# DA14531 register map
Vendor: Dialog; Series: DA14531; File version: 1.2
CPU: CM0 r1p0, little endian, MPU, FPU, 3 interrupt priority bits
Registers are 16-bit, read-write, reset 0x0 unless marked. A register's access mark holds for its fields unless they carry their own. Offsets are from the block's base; [hi:lo] are bit positions; <NAME> marks a mode.

## CRG_TOP — CRG_TOP registers
Base 0x50000000
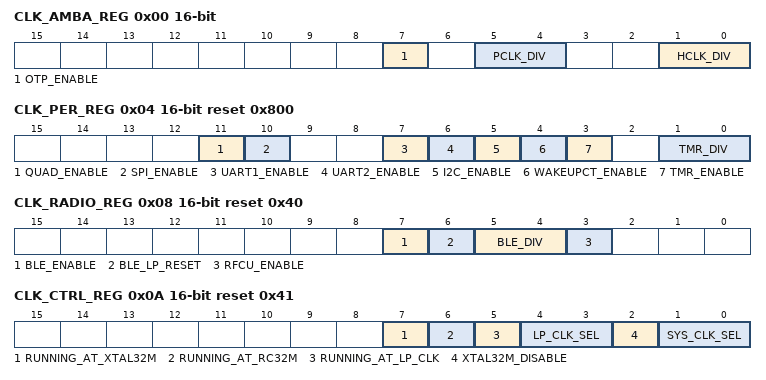
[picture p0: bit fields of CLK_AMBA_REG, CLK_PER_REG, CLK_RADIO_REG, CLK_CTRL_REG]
0x00 CLK_AMBA_REG — HCLK, PCLK, divider and clock gates
  [7] OTP_ENABLE — Clock enable for OTP controller
  [5:4] PCLK_DIV — APB interface clock (PCLK). Divider is cascaded with HCLK_DIV. PCLK is HCLK divided by: 0x0: divide by 1 0x1: divide by 2 0x2: divide by 4 0x3: divide by 8
  [1:0] HCLK_DIV — AHB interface and microprocessor clock (HCLK). HCLK is source clock divided by: 0x0: divide by 1 0x1: divide by 2 0x2: divide by 4 0x3: divide by 8
0x02 CLK_FREQ_TRIM_REG — Xtal frequency trimming register
  [7:0] XTAL32M_TRIM — Xtal frequency fine trimming register. 0x00: highest frequency 0xFF: lowest frequency
0x04 CLK_PER_REG reset 0x800 — Peripheral divider register
  [11] QUAD_ENABLE — Enable the Quadrature clock
  [10] SPI_ENABLE — Enable SPI clock
  [7] UART1_ENABLE — Enable UART1 clock
  [6] UART2_ENABLE — Enable UART2 clock
  [5] I2C_ENABLE — Enable I2C clock
  [4] WAKEUPCT_ENABLE — Enable Wakeup CaptureTimer clock
  [3] TMR_ENABLE — Enable TIMER0 and TIMER2 clock
  [1:0] TMR_DIV — Division factor for TIMER0 0x0: divide by 1 0x1: divide by 2 0x2: divide by 4 0x3: divide by 8
0x08 CLK_RADIO_REG reset 0x40 — Radio PLL control register
  [7] BLE_ENABLE — Enable the BLE core clocks
  [6] BLE_LP_RESET — Reset for the BLE LP timer
  [5:4] BLE_DIV — Division factor for BLE core blocks 0x0: divide by 1 0x1: divide by 2 0x2: divide by 4 0x3: divide by 8 The programmed frequency should not be lower than 8 MHz and not faster than the programmed CPU clock frequency. Refer also to BLE_CNTL2_REG[BLE_CLK_SEL].
  [3] RFCU_ENABLE — Enable the RF control Unit clock
0x0A CLK_CTRL_REG reset 0x41 — Clock control register
  [7] RUNNING_AT_XTAL32M ro — Indicates that the XTAL32M clock is used as clock, and may not be switched off
  [6] RUNNING_AT_RC32M ro — Indicates that the RC32M clock is used as clock
  [5] RUNNING_AT_LP_CLK ro — Indicates that either the LP_CLK is being used as system clock
  [4:3] LP_CLK_SEL — Sets the clock source of the LowerPower clock 0x0: RC32K 0x1: RCX 0x2: XTAL32K through the oscillator with an external Crystal. 0x3: XTAL32K through an external square wave generator (set PID of P0[3] to FUNC_GPIO) Change this setting before using this clock, and while RUNNING_AT_LP_CLK == 0.
  [2] XTAL32M_DISABLE — Setting this bit instantaneously disables the 32 MHz crystal oscillator. Also, after sleep/wakeup cycle, the oscillator will not be enabled. This bit may not be set to '1'when "RUNNING_AT_XTAL32M is '1' to prevent deadlock. After resetting this bit, wait for XTAL32M_SETTLED or XTAL32M_TRIM_READY to become '1' before switching to XTAL32M clock source.
  [1:0] SYS_CLK_SEL — Selects the clock source. 0x0: XTAL32M (check the XTAL32M_SETTLED and XTAL32M_TRIM_READY bits!!) 0x1: RC32M 0x2/0x3: LP_CLK
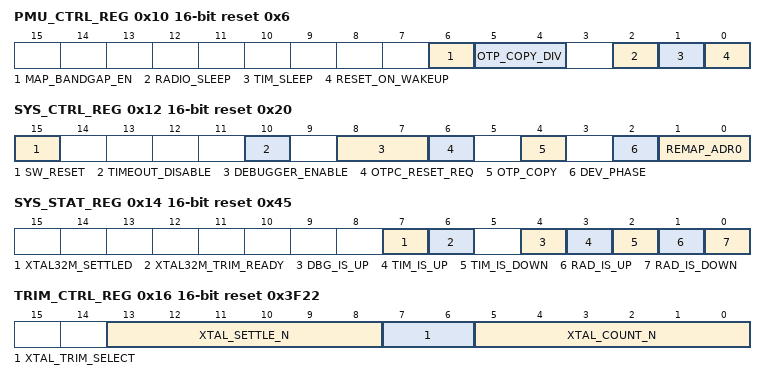
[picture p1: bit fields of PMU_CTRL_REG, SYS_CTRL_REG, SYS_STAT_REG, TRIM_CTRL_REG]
0x10 PMU_CTRL_REG reset 0x6 — Power Management Unit control register
  [6] MAP_BANDGAP_EN — Enable wakeup diagnostics mapping. When set, these functions are mapped (please set direction to output) P0[2]: BANDGAP_ENABLE P0[1]: Power WOKENUP Note: P0[2] assigned also to SWD_CLK, thus the debugger must be detached before entering into sleep mode with MAP_BANDGAP_EN=1. Refer also to SYS_STAT_REG->DBG_IS_UP.
  [5:4] OTP_COPY_DIV — Sets the HCLK division during OTP mirroring
  [2] RADIO_SLEEP — Put the digital part of the radio in powerdown
  [1] TIM_SLEEP — Put PD_TIM in powerdown
  [0] RESET_ON_WAKEUP — Perform a Hardware Reset after waking up. Booter will be started.
0x12 SYS_CTRL_REG reset 0x20 — System Control register
  [15] SW_RESET wo — Writing a '1' to this bit will reset the device, except for: SYS_CTRL_REG CLK_FREQ_TRIM_REG ...
  [10] TIMEOUT_DISABLE — Disables timeout in Power statemachine. By default, the statemachine continues if after 2 ms the blocks are not started up. This can be read back from ANA_STATUS_REG.
  [8:7] DEBUGGER_ENABLE — Enable the debugger. This bit is set by the booter according to the OTP header. If not set, the SWDIO and SW_CLK can be used as gpio ports. 0x0: no debugger enabled. 0x1: SW_CLK = P0[2], SW_DIO=P0[5] 0x2: SW_CLK = P0[2], SW_DIO=P0[1] 0x3: SW_CLK = P0[2], SW_DIO=P0[10]
  [6] OTPC_RESET_REQ — Reset request for the OTP controller.
  [4] OTP_COPY — Enables OTP to SysRAM copy action after waking up PD_SYS
  [2] DEV_PHASE — Sets the development phase mode. If this bit is set, in combination with the OTP_COPY bit, the OTP DMA will emulate the OTP mirroring to System RAM. No actual writing to RAM is done, but the exact same amount of time is spend as if the mirroring would take place. This is to mimic the behavior as if the System Code is already in OTP, and the mirroring takes place after waking up, but the (development) code still resides in an external source. If this bit is set to '0' and OTP_COPY='1', then the OTP DMA will actually do the OTP mirroring at wakeup.
  [1:0] REMAP_ADR0 — Controls which memory is located at address 0x0000 for execution. 0x0: ROM 0x1: OTP 0x2: RAM (SysRAM1) 0x3: RAM (SysRAM3, 28 kBytes offset) This bitfield only takes affect after a Software Reset.
0x14 SYS_STAT_REG reset 0x45 — System status register
  [7] XTAL32M_SETTLED ro — Indicates that XTAL32M has had its settle time, as defined by TRIM_CTRL_REG[XTAL_SETTLE_N]
  [6] XTAL32M_TRIM_READY ro — Indicates that XTAL trimming mechanism is ready, i.e. the trimming equals CLK_FREQ_TRIM_REG.
  [4] DBG_IS_UP ro — Indicates that the SW debugger is attached and in connection with the ARM.
  [3] TIM_IS_UP ro — Indicates that PD_TIM is functional
  [2] TIM_IS_DOWN ro — Indicates that PD_TIM is in power down
  [1] RAD_IS_UP ro — Indicates that PD_RAD is functional
  [0] RAD_IS_DOWN ro — Indicates that PD_RAD is in power down
0x16 TRIM_CTRL_REG reset 0x3F22 — Control trimming of the XTAL32M
  [13:8] XTAL_SETTLE_N — Designates that the XTAL can be safely used as the CPU clock. When XTAL_CLK_CNT reases this value, the signal XTAL32M_SETTLED bit in the SYS_STAT_REG will be set. Counts in steps of 64 xtal clock-cycles.
  [7:6] XTAL_TRIM_SELECT — Select which source controls the XTAL trimming 0b00: xtal counter. Starts XTAL32M_START_REG[XTAL32M_START] after COUNT_N * 32 xtal pulses trim is changed to CLK_FREQ_TRIM_REG[XTAL32M_TRIM]. 0b01: xtal OK filter. Starts with CLK_FREQ_TRIM_REG[XTAL32M_START], when xtal amplitude is ramping is changed to CLK_FREQ_TRIM_REG[XTAL32M_TRIM]. 0b10: statically forced off. Only uses CLK_FREQ_TRIM_REG[XTAL32M_TRIM]. 0b11: xtal OK filter, 2 stage. Starts with CLK_FREQ_TRIM_REG[XTAL32M_START] switches to CLK_FREQ_TRIM_REG[XTAL32M_RAMP] after timeout (32us), and switches to CLK_FREQ_TRIM_REG[XTAL32M_TRIM] when xtal amplitude is ramping up.
  [5:0] XTAL_COUNT_N — Defines the number of XTAL cycles to be counted, before the xtal trimming is applied, in steps of 64 cycles. 0x01: 64 0x02: 128 0x3f: 4032
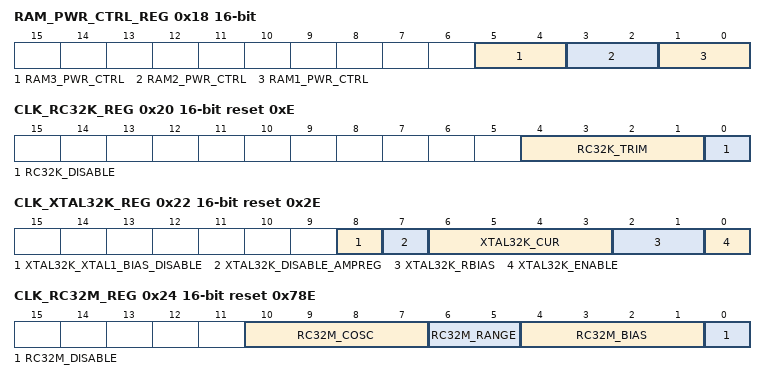
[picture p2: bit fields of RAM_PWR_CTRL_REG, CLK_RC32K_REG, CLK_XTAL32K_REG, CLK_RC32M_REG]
0x18 RAM_PWR_CTRL_REG — Control power state of System RAMS
  [5:4] RAM3_PWR_CTRL — See description of RAM1_PWR_CTRL.
  [3:2] RAM2_PWR_CTRL — See description of RAM1_PWR_CTRL.
  [1:0] RAM1_PWR_CTRL — Power state control of the individual RAMs. May only change when the memory isn't accessed. When in Active or Sleep mode: 0x0: Normal operation 0x1: Normal operation 0x2: Retained (no access possible) 0x3: Off (memory content corrupted) When in Extended Sleep, Deep Sleep or Hibernation mode 0x0: Retained 0x1: Off (memory content corrupted) 0x2: Retained 0x3: Off (memory content corrupted)
0x20 CLK_RC32K_REG reset 0xE — 32 kHz RC oscillator register
  [4:1] RC32K_TRIM — 0000 = lowest frequency 0111 = default 1111 = highest frequency
  [0] RC32K_DISABLE — Instantly disables the 32kHz RC oscillator Sleep cycles cannot happen with this clock disabled.
0x22 CLK_XTAL32K_REG reset 0x2E — 32 kHz XTAL oscillator register
  [8] XTAL32K_XTAL1_BIAS_DISABLE
  [7] XTAL32K_DISABLE_AMPREG — Setting this bit disables the amplitude regulation of the XTAL32kHz oscillator. Set this bit to '1' for an external clock to XTAL32Kp Keep this bit '0' with a crystal between XTAL32Kp and XTAL32Km
  [6:3] XTAL32K_CUR — Bias current for the 32kHz XTAL oscillator. 0000 is minimum, 1111 is maximum, 0011 is default. For each application there is an optimal setting for which the start-up behavior is optimal
  [2:1] XTAL32K_RBIAS — Setting for the bias resistor. 00 is maximum, 11 is minimum. Prefered setting will be provided by Dialog
  [0] XTAL32K_ENABLE — Enables the 32kHz XTAL oscillator. Also set GP_DATA_REG[P03_P04_FILT_DIS] = 1 for lowest current consumption.
0x24 CLK_RC32M_REG reset 0x78E — Fast RC control register
  [10:7] RC32M_COSC — C-adjust of RC-oscillator A higher value of COSC results in a lower frequency
  [6:5] RC32M_RANGE — Coarse adjust A higher value of RANGE results in a higher frequency, values 2 and 3 are equal
  [4:1] RC32M_BIAS — Bias adjustment
  [0] RC32M_DISABLE — Instantly disables the 32MHz RC oscillator Disabling of the oscillator during sleep happens automatically.
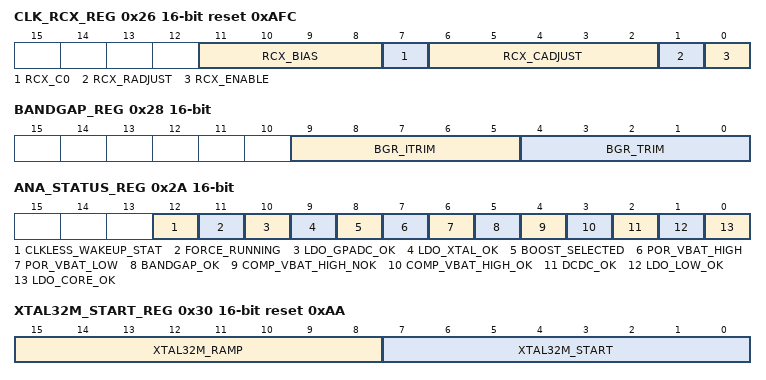
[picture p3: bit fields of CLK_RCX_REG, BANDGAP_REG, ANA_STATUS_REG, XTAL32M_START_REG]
0x26 CLK_RCX_REG reset 0xAFC — RCX-oscillator control register
  [11:8] RCX_BIAS — LDO bias current. 0x0: minimum 0xF: maximum
  [7] RCX_C0 — Add unit capacitance to RC-time delay.
  [6:2] RCX_CADJUST — Adjust capacitance part of RC-time delay. 0x00: minimum capacitance 0x1F: maximum capacitance
  [1] RCX_RADJUST — Adjust resistance part of RC-time delay. Lower resistance increases power consumption. 0x0: maximum resistance 0x1: minimum resistance
  [0] RCX_ENABLE — Enable the RCX oscillator
0x28 BANDGAP_REG — Bandgap trimming
  [9:5] BGR_ITRIM — Trim setting for bandgap bias current 10000 -> -25% .... 11111 -> ~0% 00000 -> ~0% (typ) ... 01111 -> +32%
  [4:0] BGR_TRIM — Trim setting for bandgap voltage 10000 -> -6.4% .... 11111 -> ~0% 00000 -> ~0% (typ) ... 01111 -> +5.8%
0x2A ANA_STATUS_REG — Status bit of analog (power management) circuits
  [12] CLKLESS_WAKEUP_STAT ro — Indicates the output of the Clockless wakeup XOR tree. If this signal is '0', the chip will wake up. Use the HIBERN_WKUP_POLARITY bit to set the value to '1' before going into hibernation mode.
  [11] FORCE_RUNNING ro
  [10] LDO_GPADC_OK ro — Indicates that LDO_GPADC output is OK
  [9] LDO_XTAL_OK ro — Indicates that LDO_XTAL output is OK
  [8] BOOST_SELECTED ro — 0: Buck mode detected 1: Boost mode detected
  [7] POR_VBAT_HIGH ro — Output of VBAT_HIGH supply rail voltage monitoring circuit. 0: Voltage level on VBAT_HIGH is lower than POR VBAT_HIGH threshold VTH_L (rail not ok, will result in reset if not masked) 1: Voltage level on VBAT_HIGH is higher than POR VBAT_HIGH threshold VTH_H (rail ok, reset released)
  [6] POR_VBAT_LOW ro — Output of VBAT_LOW supply rail voltage monitoring circuit. 0: Voltage level on VBAT_LOW is lower than POR VBAT_LOW threshold VTH_L (rail not ok, will result in reset if not masked) 1: Voltage level on VBAT_LOW is higher than POR VBAT_LOW threshold VTH_H (rail ok, reset released)
  [5] BANDGAP_OK ro — Indicates that BANDGAP is OK
  [4] COMP_VBAT_HIGH_NOK ro — Indicates that VBAT_HIGH < VBAT_LOW -50 mV
  [3] COMP_VBAT_HIGH_OK ro — Indicates that VBAT_HIGH > VBAT_LOW +50 mV
  [2] DCDC_OK ro — Indicates that VBAT_LOW (buck mode) or VBAT_HIGH (boost mode) is OK
  [1] LDO_LOW_OK ro — Indicates that LDO_LOW output is OK (only valid for high current mode)
  [0] LDO_CORE_OK ro — Indicates that LDO_CORE output is OK
0x30 XTAL32M_START_REG reset 0xAA — Trim values for XTAL32M
  [15:8] XTAL32M_RAMP — Xtal frequency trimming register. 0x00 : highest frequency 0xFF :lowest frequency
  [7:0] XTAL32M_START — Xtal frequency trimming register. 0x0 = highest frequency 0xF = lowest frequency.
0x32 XTAL32M_TRSTAT_REG — Read back value of current XTAL trimming
  [7:0] XTAL32M_TRSTAT ro — Reads value of the current XTAL trimming
0x34 XTALRDY_CTRL_REG — Control register for XTALRDY IRQ
  [7:0] XTALRDY_CNT — Number of 32kHz cycles between the crystal is enabled, and the XTALRDY_IRQ is fired. 0x00: no interrupt
0x36 XTALRDY_STAT_REG
  [7:0] XTALRDY_STAT ro
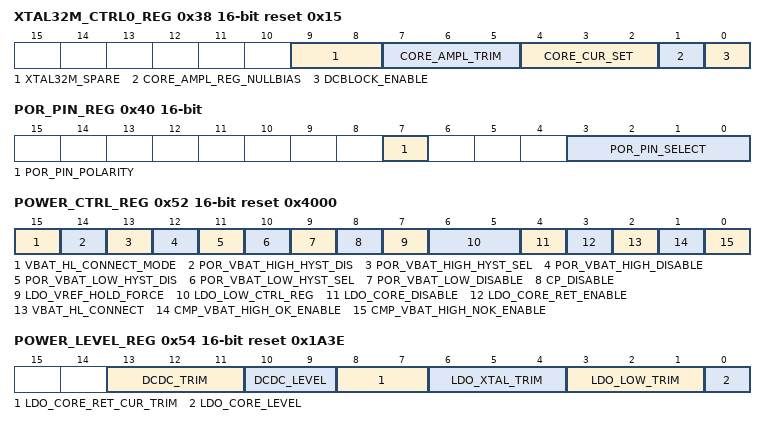
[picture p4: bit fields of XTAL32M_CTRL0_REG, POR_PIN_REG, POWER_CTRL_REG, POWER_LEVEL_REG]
0x38 XTAL32M_CTRL0_REG reset 0x15 — Control bits for XTAL32M
  [9:8] XTAL32M_SPARE
  [7:5] CORE_AMPL_TRIM — Core amplitude trimming
  [4:2] CORE_CUR_SET — Core current trim setting
  [1] CORE_AMPL_REG_NULLBIAS — Keep bias in ampl detector alive, even when there is a large drive
  [0] DCBLOCK_ENABLE — Enable dcblock/high pass filter circuit
0x40 POR_PIN_REG — Selects a GPIO pin for POR generation
  [7] POR_PIN_POLARITY — 0: Active Low 1: Active High Note: This applies only for the GPIO pin. Reset pad has a fixed polarity
  [3:0] POR_PIN_SELECT — Selects the GPIO which is used for POR generation. 0x0: GPIO pin POReset disabled 0x1: P0_0 0x2: P0_1 ... 0xB: P0_10 0xC: P0_11 0xD - 0xF: reserved
0x42 POR_TIMER_REG reset 0x18 — Time for POR to happen
  [6:0] POR_TIME — Time for the POReset to happen. Formula: Time = POR_TIME x 4096 x RC32k clock period Default value: ~3 seconds When set to 0x00, the POR TIMER is disabled.
0x50 PMU_SLEEP_REG reset 0x80 — Bandgap refresh interval during sleep
  [11:0] BG_REFRESH_INTERVAL — Defines the refresh interval of reference voltages (bandgap activation and sampling), in units of 2ms.
0x52 POWER_CTRL_REG reset 0x4000 — Power management control
  [15] VBAT_HL_CONNECT_MODE — Sets the control mode fo the switch between VBAT_HIGH and VBAT_LOW 0: Manual (default) 1: Automatic (boost mode only)
  [14] POR_VBAT_HIGH_HYST_DIS
  [13] POR_VBAT_HIGH_HYST_SEL
  [12] POR_VBAT_HIGH_DISABLE — Disable por_vbat_high circuit
  [11] POR_VBAT_LOW_HYST_DIS
  [10] POR_VBAT_LOW_HYST_SEL
  [9] POR_VBAT_LOW_DISABLE — Disable por_vbat_low circuit
  [8] CP_DISABLE — Disables LDO_CORE charge-pump circuit
  [7] LDO_VREF_HOLD_FORCE — Forces LDO references in HOLD mode
  [6:5] LDO_LOW_CTRL_REG — 00: High-current mode in active, LDO_LOW OFF in sleep 01: LDO_LOW OFF 10: Low-current mode in active, Low-current mode in sleep 11: High-current mode in active, Low-current mode in sleep
  [4] LDO_CORE_DISABLE — Disables LDO_CORE
  [3] LDO_CORE_RET_ENABLE — LDO_CORE_RETENTION 0: Disabled 1: Enabled
  [2] VBAT_HL_CONNECT — Switch between VBAT_HIGH and VBAT_LOW 0: Open 1: Closed
  [1] CMP_VBAT_HIGH_OK_ENABLE — Enable cmp_vbat_high_ok
  [0] CMP_VBAT_HIGH_NOK_ENABLE — Enable cmp_vbat_high_nok
0x54 POWER_LEVEL_REG reset 0x1A3E — Power management level and trim settings
  [13:11] DCDC_TRIM — Delta from DCDC_LEVEL nominal value 000: -75 mV 001: -50 mV 010: -25 mV 011: 0 (default) 100: +25 mV 101: +50 mV 110: +75 mV 111: +100 mV
  [10:9] DCDC_LEVEL — 00: 1.1 V 01: 1.8 V (default) 10: 2.5 V 11: 3.0 V
  [8:7] LDO_CORE_RET_CUR_TRIM
  [6:4] LDO_XTAL_TRIM — Delta from 0.9 V nominal value 000: -75 mV 001: -50 mV 010: -25 mV 011: 0 (default) 100: +25 mV 101: +50 mV 110: +75 mV 111: +100 mV
  [3:1] LDO_LOW_TRIM — Delta from 1.1 V nominal value 000: -75 mV 001: -50 mV 010: -25 mV 011: 0 (default) 100: +25 mV 101: +50 mV 110: +75 mV 111: +100 mV (coldboot)
  [0] LDO_CORE_LEVEL
